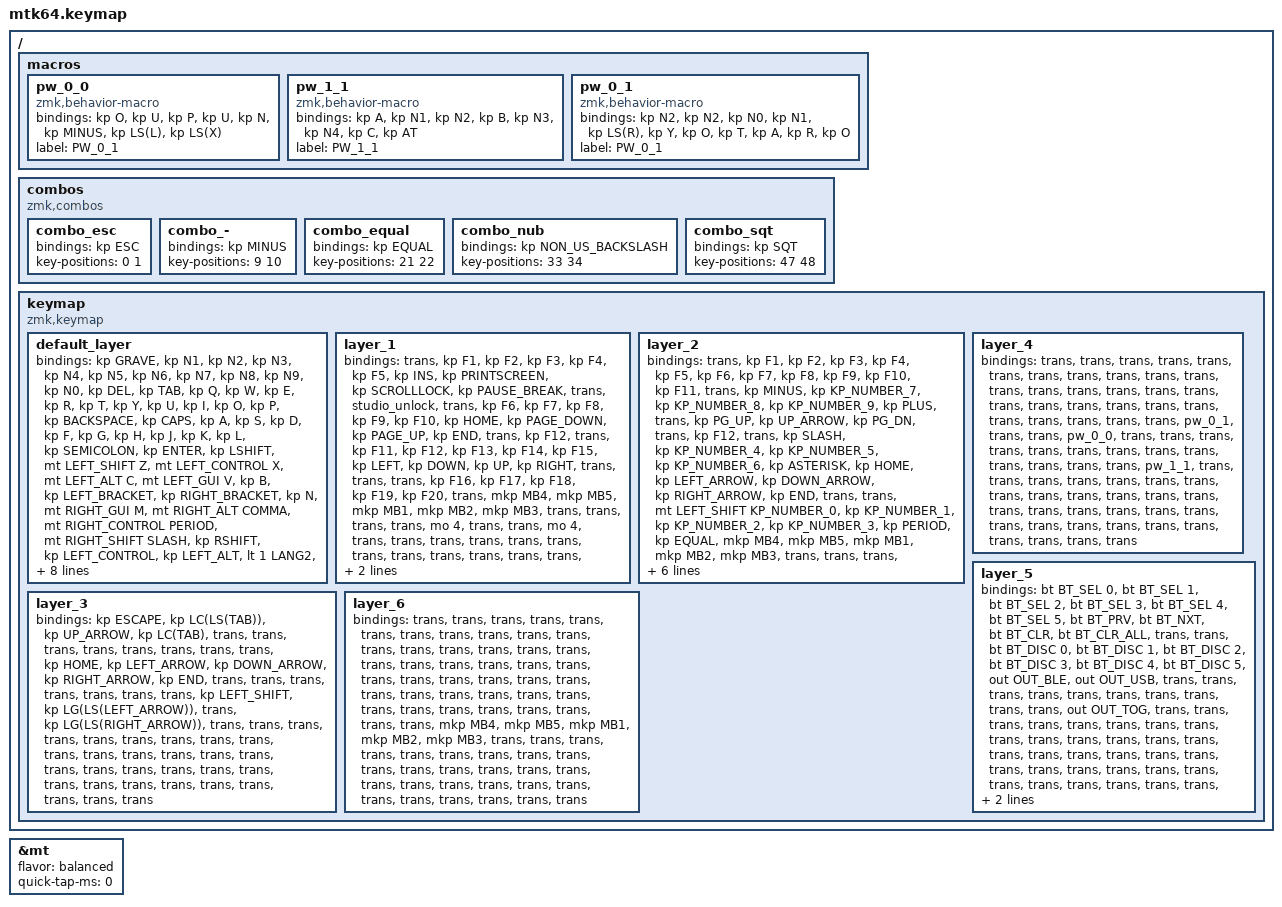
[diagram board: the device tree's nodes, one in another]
#include "keycode_japanese.h"
#include <behaviors.dtsi>
#include <dt-bindings/zmk/bt.h>
#include <dt-bindings/zmk/keys.h>
#include <dt-bindings/zmk/outputs.h>
#include <dt-bindings/zmk/pointing.h>

&mt {
    flavor = "balanced";
    quick-tap-ms = <0>;
};

/ {
    macros {
        pw_0_0: pw_0_0 {
            compatible = "zmk,behavior-macro";
            #binding-cells = <0>;
            bindings = <&kp O &kp U &kp P &kp U &kp N &kp MINUS &kp LS(L) &kp LS(X)>;
            label = "PW_0_1";
        };

        pw_1_1: pw_1_1 {
            compatible = "zmk,behavior-macro";
            #binding-cells = <0>;
            bindings = <&kp A &kp N1 &kp N2 &kp B &kp N3 &kp N4 &kp C &kp AT>;
            label = "PW_1_1";
        };

        pw_0_1: pw_0_1 {
            compatible = "zmk,behavior-macro";
            #binding-cells = <0>;
            bindings = <&kp N2 &kp N2 &kp N0 &kp N1 &kp LS(R) &kp Y &kp O &kp T &kp A &kp R &kp O>;
            label = "PW_0_1";
        };
    };

    combos {
        compatible = "zmk,combos";

        combo_esc {
            bindings = <&kp ESC>;
            key-positions = <0 1>;
        };

        combo_- {
            bindings = <&kp MINUS>;
            key-positions = <9 10>;
        };

        combo_equal {
            bindings = <&kp EQUAL>;
            key-positions = <21 22>;
        };

        combo_nub {
            bindings = <&kp NON_US_BACKSLASH>;
            key-positions = <33 34>;
        };

        combo_sqt {
            bindings = <&kp SQT>;
            key-positions = <47 48>;
        };
    };

    keymap {
        compatible = "zmk,keymap";

        default_layer {
            bindings = <
&kp GRAVE  &kp N1  &kp N2  &kp N3  &kp N4  &kp N5  &kp N6  &kp N7  &kp N8  &kp N9  &kp N0  &kp DEL  &kp TAB  &kp Q  &kp W  &kp E  &kp R  &kp T  &kp Y  &kp U  &kp I  &kp O  &kp P  &kp BACKSPACE  &kp CAPS  &kp A  &kp S  &kp D  &kp F  &kp G  &kp H  &kp J  &kp K  &kp L  &kp SEMICOLON  &kp ENTER  &kp LSHIFT  &mt LEFT_SHIFT Z  &mt LEFT_CONTROL X  &mt LEFT_ALT C  &mt LEFT_GUI V  &kp B  &kp LEFT_BRACKET  &kp RIGHT_BRACKET  &kp N  &mt RIGHT_GUI M  &mt RIGHT_ALT COMMA  &mt RIGHT_CONTROL PERIOD  &mt RIGHT_SHIFT SLASH  &kp RSHIFT  &kp LEFT_CONTROL  &kp LEFT_ALT  &lt 1 LANG2  &lt 2 SPACE  &lt 2 BACKSPACE  &lt 1 ENTER  &kp RIGHT_ALT  &kp RIGHT_CONTROL  &tog 5  &kp ENTER  &lt 3 LANG1  &lt 3 ENTER  &kp ENTER  &tog 2  &kp LANG1  &kp LANG2  &mo 1  &mo 2  &mo 3  &mo 1  &mo 2  &mo 3  &mo 1  &mo 2  &mo 3
            >;

            sensor-bindings = <
                &inc_dec_kp LEFT_ARROW RIGHT_ARROW
                &inc_dec_kp UP_ARROW   DOWN_ARROW
            >;
        };

        layer_1 {
            bindings = <
&trans  &kp F1  &kp F2  &kp F3  &kp F4  &kp F5  &kp INS  &kp PRINTSCREEN  &kp SCROLLLOCK  &kp PAUSE_BREAK  &trans  &studio_unlock  &trans  &kp F6  &kp F7  &kp F8  &kp F9  &kp F10  &kp HOME  &kp PAGE_DOWN  &kp PAGE_UP  &kp END  &trans  &kp F12  &trans  &kp F11  &kp F12  &kp F13  &kp F14  &kp F15  &kp LEFT  &kp DOWN  &kp UP  &kp RIGHT  &trans  &trans  &trans  &kp F16  &kp F17  &kp F18  &kp F19  &kp F20  &trans  &mkp MB4  &mkp MB5  &mkp MB1  &mkp MB2  &mkp MB3  &trans  &trans  &trans  &trans  &mo 4  &trans  &trans  &mo 4  &trans  &trans  &trans  &trans  &trans  &trans  &trans  &trans  &trans  &trans  &trans  &trans  &trans  &trans  &trans  &trans  &trans  &trans  &trans
            >;
        };

        layer_2 {
            bindings = <
&trans  &kp F1  &kp F2  &kp F3  &kp F4  &kp F5  &kp F6  &kp F7  &kp F8  &kp F9  &kp F10  &kp F11  &trans  &kp MINUS  &kp KP_NUMBER_7  &kp KP_NUMBER_8  &kp KP_NUMBER_9  &kp PLUS  &trans  &kp PG_UP  &kp UP_ARROW  &kp PG_DN  &trans  &kp F12  &trans  &kp SLASH  &kp KP_NUMBER_4  &kp KP_NUMBER_5  &kp KP_NUMBER_6  &kp ASTERISK  &kp HOME  &kp LEFT_ARROW  &kp DOWN_ARROW  &kp RIGHT_ARROW  &kp END  &trans  &trans  &mt LEFT_SHIFT KP_NUMBER_0  &kp KP_NUMBER_1  &kp KP_NUMBER_2  &kp KP_NUMBER_3  &kp PERIOD  &kp EQUAL  &mkp MB4  &mkp MB5  &mkp MB1  &mkp MB2  &mkp MB3  &trans  &trans  &trans  &trans  &trans  &trans  &trans  &trans  &trans  &trans  &trans  &trans  &trans  &trans  &trans  &trans  &trans  &trans  &trans  &trans  &trans  &trans  &trans  &trans  &trans  &trans  &trans
            >;

            sensor-bindings = <
                &inc_dec_kp TAB LC(TAB) 
                &inc_dec_kp PG_UP PG_DN
            >;
        };

        layer_3 {
            bindings = <
&kp ESCAPE  &kp LC(LS(TAB))  &kp UP_ARROW  &kp LC(TAB)  &trans  &trans  &trans  &trans  &trans  &trans  &trans  &trans  &kp HOME  &kp LEFT_ARROW  &kp DOWN_ARROW  &kp RIGHT_ARROW  &kp END  &trans  &trans  &trans  &trans  &trans  &trans  &trans  &kp LEFT_SHIFT  &kp LG(LS(LEFT_ARROW))  &trans  &kp LG(LS(RIGHT_ARROW))  &trans  &trans  &trans  &trans  &trans  &trans  &trans  &trans  &trans  &trans  &trans  &trans  &trans  &trans  &trans  &trans  &trans  &trans  &trans  &trans  &trans  &trans  &trans  &trans  &trans  &trans  &trans  &trans  &trans  &trans
            >;
        };

        layer_4 {
            bindings = <
&trans  &trans  &trans  &trans  &trans  &trans  &trans  &trans  &trans  &trans  &trans  &trans  &trans  &trans  &trans  &trans  &trans  &trans  &trans  &trans  &trans  &trans  &trans  &trans  &trans  &trans  &trans  &trans  &pw_0_1  &trans  &trans  &pw_0_0  &trans  &trans  &trans  &trans  &trans  &trans  &trans  &trans  &trans  &trans  &trans  &trans  &trans  &pw_1_1  &trans  &trans  &trans  &trans  &trans  &trans  &trans  &trans  &trans  &trans  &trans  &trans  &trans  &trans  &trans  &trans  &trans  &trans  &trans  &trans  &trans  &trans  &trans  &trans  &trans  &trans  &trans  &trans  &trans
            >;
        };

        layer_5 {
            bindings = <
&bt BT_SEL 0  &bt BT_SEL 1  &bt BT_SEL 2  &bt BT_SEL 3  &bt BT_SEL 4  &bt BT_SEL 5  &bt BT_PRV  &bt BT_NXT  &bt BT_CLR  &bt BT_CLR_ALL  &trans  &trans  &bt BT_DISC 0  &bt BT_DISC 1  &bt BT_DISC 2  &bt BT_DISC 3  &bt BT_DISC 4  &bt BT_DISC 5  &out OUT_BLE  &out OUT_USB  &trans  &trans  &trans  &trans  &trans  &trans  &trans  &trans  &trans  &trans  &out OUT_TOG  &trans  &trans  &trans  &trans  &trans  &trans  &trans  &trans  &trans  &trans  &trans  &trans  &trans  &trans  &trans  &trans  &trans  &trans  &trans  &trans  &trans  &trans  &trans  &trans  &trans  &trans  &trans  &trans  &trans  &trans  &trans  &trans  &trans  &trans  &trans  &trans  &trans  &trans  &trans  &trans  &trans  &trans  &trans  &trans
            >;
        };

        layer_6 {
            bindings = <
&trans  &trans  &trans  &trans  &trans  &trans  &trans  &trans  &trans  &trans  &trans  &trans  &trans  &trans  &trans  &trans  &trans  &trans  &trans  &trans  &trans  &trans  &trans  &trans  &trans  &trans  &trans  &trans  &trans  &trans  &trans  &trans  &trans  &trans  &trans  &trans  &trans  &trans  &trans  &trans  &trans  &trans  &trans  &mkp MB4  &mkp MB5  &mkp MB1  &mkp MB2  &mkp MB3  &trans  &trans  &trans  &trans  &trans  &trans  &trans  &trans  &trans  &trans  &trans  &trans  &trans  &trans  &trans  &trans  &trans  &trans  &trans  &trans  &trans  &trans  &trans  &trans  &trans  &trans  &trans
            >;
        };
    };
};
